# A31T21x register map
Vendor: ABOV Semiconductor Co., Ltd.; Series: A31T21x; File version: 1.0
CPU: CM0PLUS r0p1, little endian, no MPU, no FPU, VTOR, 2 interrupt priority bits
Registers are 32-bit, read-write, reset 0x0 unless marked. A register's access mark holds for its fields unless they carry their own. Offsets are from the block's base; [hi:lo] are bit positions; {n}, {i} and the like mark numbered series.

## ADC — 12-BIT A/D CONVERTER
Base 0x40003000
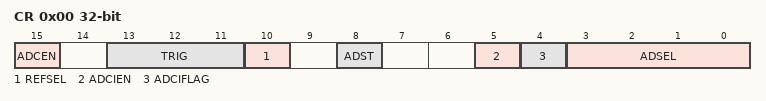
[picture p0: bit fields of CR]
0x00 CR — A/D Converter Control Register
  [15] ADCEN — A/DC Module Enable bit (The A/DC is automatically disabled at power down mode)
    0=DISABLE_ADC (Disable A/DC module operation); 1=ENABLE_ADC (Enable A/DC module operation)
  [13:11] TRIG — A/DC Trigger Signal Selection bits
    0=ADST; 1=T10_A_MATCH (Timer 10 A-match signal); 2=T11_A_MATCH (Timer 11 A-match signal); 3=T12_A_MATCH (Timer 12 A-match signal); 4=T30_SIGNAL (A/DC trigger signal from timer 30)
  [10] REFSEL — A/DC Reference Selection bit
    0=VDD (Select analog power (VDD)); 1=AVREF (Select external reference (AVREF))
  [8] ADST — A/DC Conversion Start bit. This bit is automatically cleared to "0b" after operation
    0=NONE (No effect); 1=START_AD_CONVERSION (Trigger signal generation for conversion start)
  [5] ADCIEN — A/DC Interrupt Enable bit
    0=DISABLE_ADC_INT (Disable A/DC interrupt); 1=ENABLE_ADC_INT (Enable A/DC interrupt)
  [4] ADCIFLAG — A/DC Interrupt Flag bit
    0=ADC_IF_CLR (No request occurred); 1=ADC_IF_SET (Request occurred, This bit is cleared to '0' when write '1'.)
  [3:0] ADSEL — A/D Converter Channel Selection bits
    {v}=AN{v} (v=0..13)
0x04 DR ro — A/D Converter Data Register
  [11:0] ADDATA — A/D Converter Result Data bits
0x08 PREDR reset 0xF (reset mask 0x1F) — A/D Converter Prescaler Data Register
  [5:0] PRED — A/D Converter Prescaler Data bits.

## TOUCH
Base 0x40003600
{0x0+8i} SUM_CH{i}_F0 ro (i=0..23) — Touch Sensor Channel 0~23 Sum Register
  [15:0] SUM_CH_DATA — Touch Sensor Channel n Frequency Sum Register
{0x4+8i} SUM_CH{i}_F1 ro (i=0..23) — Touch Sensor Channel 0~23 Sum Register
  [15:0] SUM_CH_DATA — Touch Sensor Channel n Frequency Sum Register
{0xC0+4i} SCO{i} (i=0..23) — Touch Sensor Offset Capacitor Selection Register for CH0~23
  [12:0] SCO — Touch Sensor Offset Capacitor Selection
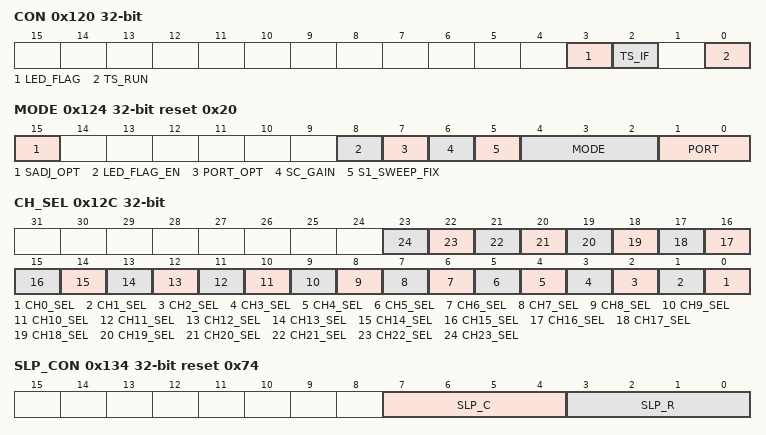
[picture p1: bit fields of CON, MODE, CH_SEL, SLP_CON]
0x120 CON — Touch Sensor Control Register
  [3] LED_FLAG — LED Start Signal Sensing
  [2] TS_IF — Touch Sensor Interrupt Flag
  [0] TS_RUN — Touch Sensor Enable
0x124 MODE reset 0x20 — Touch Sensor Mode Register
  [15] SADJ_OPT — Channel-Adjust path enable
  [8] LED_FLAG_EN — LED FLAG enable bit
  [7] PORT_OPT — Determine the channel and timing to apply PORT[1:0]
  [6] SC_GAIN — Gain Calibration Capacitor Enable 0: Gain Calibration Capacitor Disable (Default) 1: Gain Calibration Capacitor Enable
  [5] S1_SWEEP_FIX — S1 width sweep fix 0: S1 width = TS_S1_WIDTH + random value 1: S1 width = TS_S1_WIDTH
  [4:2] MODE — Touch Sensor Mode
  [1:0] PORT — Port Configuration During Inactive Status 00: Input Floating 01: Output Low 10: Output High
0x128 SUM_CNT reset 0x1 — Touch Sensor Sum Repeat Count Register
  [7:0] TS_SUM_CNT — Touch Sensor Sum Repeat Count
0x12C CH_SEL — Touch Sensor Channel Selection Register
  [n] CH{n}_SEL (n=0..23) — Touch Sensor Channel Selection Register 0: Disable (Default) 1: Enable Touch Key
0x130 S1_WIDTH reset 0x20 — Touch Sensor Sum Repeat Count Register
  [7:0] TS_S1_WIDTH — Touch Sensor Sum Repeat Count
0x134 SLP_CON reset 0x74 — Touch Sensor Low Pass Filter Control Register
  [7:4] SLP_C — Capacitor Trimming for Input Low Pass Filter
  [3:0] SLP_R — Resistor Trimming for Input Low Pass Filter
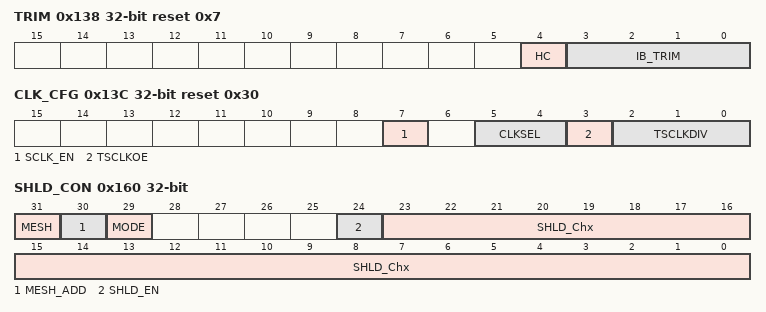
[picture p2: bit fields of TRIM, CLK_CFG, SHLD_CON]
0x138 TRIM reset 0x7 — Touch Sensor Trimming Register
  [4] HC — High Current Enable
  [3:0] IB_TRIM — Current Bias Trimming Value
0x13C CLK_CFG reset 0x30 — Touch Sensor Clock Configuration Register
  [7] SCLK_EN — Select touch clock source
  [5:4] CLKSEL — Touch Clock source select
  [3] TSCLKOE — Divided Touch Sensor Clock Output Enable
  [2:0] TSCLKDIV — Touch Sensor Clock Divider(Refer to TRIM_OSC)
0x140 TRIM_OSC reset 0xB8 — Touch Sensor RING Oscillator Trimming Selection Register
  [7:0] TRIM_OSC — Touch Sensor RING Oscillator Trimming Selection
0x144 DELTA_OSC reset 0xFF — Touch Sensor RING Oscillator Delta Register
  [5:0] TS_DELTA_OSC — Frequency of Touch clock A = 16MHz+((TRIM_OSC_+DELTA_OSC-20H)*0.25%
0x148 TLED reset 0x30 — LED stable time Register
  [11:0] TLED — LED stable Time
0x14C VHS reset 0x280 — Touch Sensor High Sense Voltage Register
  [9:0] VHS — Touch Sensor High Sense Voltage register
0x150 VREF reset 0x210 — Touch Sensor COMP Reference Voltage Register
  [9:0] VREF — Touch Sensor COMP Reference voltage register
0x160 SHLD_CON — Touch Sensor Shield Channel Control Register
  [31] MESH — Shield mesh enable bit
  [30] MESH_ADD — Additional shield mesh enable bit
  [29] MODE — Shield mode bit
  [24] SHLD_EN — Shield enable bit
  [23:0] SHLD_Chx — Shield channel selection bits
